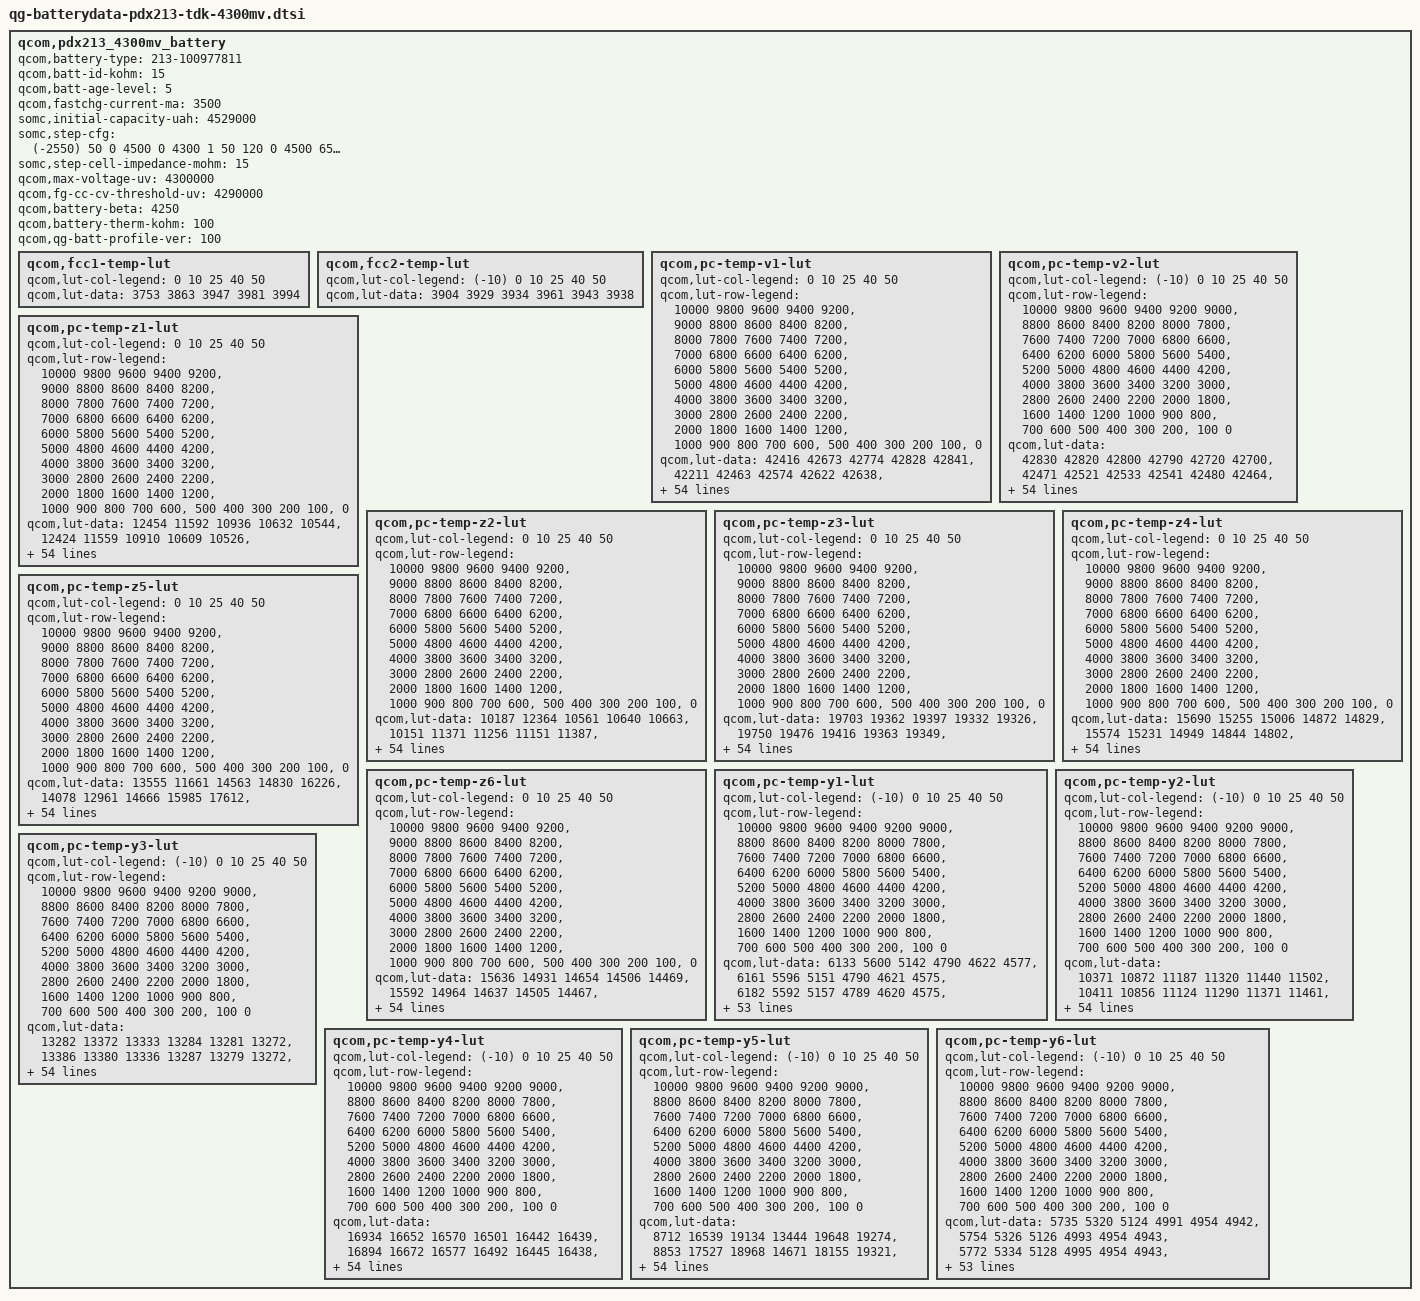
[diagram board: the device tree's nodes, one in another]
qcom,pdx213_4300mv_battery {
	/* Added or Modified by SOMC */
	qcom,battery-type = "213-100977811";
	qcom,batt-id-kohm = <15>;
	qcom,batt-age-level = <5>;
	qcom,fastchg-current-ma = <3500>;
	somc,initial-capacity-uah = <4529000>;
	somc,step-cfg = <
		(-2550) 50    0 4500    0 4300 1
		   50  120    0 4500  650 4300 2
		  120  150    0 4100 1750 4300 3
		  120  150 4100 4200 1300 4300 3
		  120  150 4200 4500  850 4300 3
		  150  200    0 4100 2150 4300 3
		  150  200 4100 4200 1500 4300 3
		  150  200 4200 4500  850 4300 3
		  200  450    0 4150 3050 4300 3
		  200  450 4150 4200 2150 4300 3
		  200  450 4200 4500 1300 4300 3
		  450  550    0 4500 1300 4200 4
		  550 2550    0 4500    0 4200 5
	>;
	somc,step-cell-impedance-mohm = <15>;

	/* Prepared by Qualcomm */
    /* 4764153_SoMC_Licht_4005mAh_averaged_MasterSlave_Aug31st2020 */
    qcom,max-voltage-uv = <4300000>;
    qcom,fg-cc-cv-threshold-uv = <4290000>;
    /* qcom,fastchg-current-ma = <1500>; */
    /* qcom,batt-id-kohm = <0>; */
    qcom,battery-beta = <4250>;
    qcom,battery-therm-kohm = <100>;
    /* qcom,battery-type = "4764153_SoMC_Licht_4005mAh_averaged_MasterSlave_Aug31st2020"; */
    qcom,qg-batt-profile-ver = <100>;

	qcom,fcc1-temp-lut {
		qcom,lut-col-legend = <0 10 25 40 50>;
		qcom,lut-data = <3753 3863 3947 3981 3994>;
	};

	qcom,fcc2-temp-lut {
		qcom,lut-col-legend = <(-10) 0 10 25 40 50>;
		qcom,lut-data = <3904 3929 3934 3961 3943 3938>;
	};

	qcom,pc-temp-v1-lut {
		qcom,lut-col-legend = <0 10 25 40 50>;
		qcom,lut-row-legend = <10000 9800 9600 9400 9200>,
			<9000 8800 8600 8400 8200>,
			<8000 7800 7600 7400 7200>,
			<7000 6800 6600 6400 6200>,
			<6000 5800 5600 5400 5200>,
			<5000 4800 4600 4400 4200>,
			<4000 3800 3600 3400 3200>,
			<3000 2800 2600 2400 2200>,
			<2000 1800 1600 1400 1200>,
			<1000 900 800 700 600>,
			<500 400 300 200 100>,
			<0>;
		qcom,lut-data = <42416 42673 42774 42828 42841>,
			<42211 42463 42574 42622 42638>,
			<42012 42243 42369 42415 42433>,
			<41815 42025 42156 42208 42227>,
			<41623 41819 41940 41999 42018>,
			<41435 41621 41731 41792 41811>,
			<41251 41429 41526 41586 41607>,
			<41072 41239 41328 41384 41407>,
			<40902 41053 41137 41188 41210>,
			<40741 40874 40951 40995 41015>,
			<40579 40700 40770 40808 40827>,
			<40405 40531 40592 40626 40645>,
			<40231 40365 40423 40451 40469>,
			<40079 40205 40263 40285 40301>,
			<39950 40055 40110 40127 40139>,
			<39828 39920 39962 39975 39983>,
			<39702 39785 39827 39835 39841>,
			<39577 39630 39671 39690 39698>,
			<39444 39458 39431 39496 39516>,
			<39290 39277 39160 39257 39289>,
			<39127 39060 38994 39067 39092>,
			<38978 38856 38896 38937 38950>,
			<38831 38756 38812 38827 38830>,
			<38709 38704 38727 38723 38723>,
			<38633 38657 38646 38628 38629>,
			<38578 38602 38568 38540 38541>,
			<38534 38546 38490 38458 38457>,
			<38496 38489 38418 38383 38377>,
			<38463 38431 38355 38314 38304>,
			<38430 38375 38298 38251 38236>,
			<38396 38326 38248 38194 38174>,
			<38363 38281 38202 38143 38118>,
			<38329 38240 38160 38096 38066>,
			<38296 38205 38120 38048 38012>,
			<38259 38171 38081 38002 37958>,
			<38220 38130 38039 37952 37901>,
			<38176 38086 37994 37897 37837>,
			<38115 38030 37942 37835 37766>,
			<38022 37945 37867 37759 37685>,
			<37908 37833 37763 37665 37593>,
			<37789 37712 37648 37559 37488>,
			<37654 37576 37518 37433 37361>,
			<37509 37433 37378 37297 37225>,
			<37363 37280 37226 37154 37088>,
			<37276 37175 37120 37055 36993>,
			<37199 37118 37067 37004 36944>,
			<37172 37096 37048 36991 36929>,
			<37145 37076 37036 36976 36916>,
			<37111 37054 37013 36954 36895>,
			<37036 36987 36941 36865 36780>,
			<36787 36713 36644 36548 36451>,
			<36343 36276 36211 36115 36018>,
			<35784 35714 35656 35559 35461>,
			<35024 34949 34910 34816 34713>,
			<33747 33698 33765 33675 33563>,
			<30000 30000 30000 30000 30000>;
	};

	qcom,pc-temp-v2-lut {
		qcom,lut-col-legend = <(-10) 0 10 25 40 50>;
		qcom,lut-row-legend = <10000 9800 9600 9400 9200 9000>,
			<8800 8600 8400 8200 8000 7800>,
			<7600 7400 7200 7000 6800 6600>,
			<6400 6200 6000 5800 5600 5400>,
			<5200 5000 4800 4600 4400 4200>,
			<4000 3800 3600 3400 3200 3000>,
			<2800 2600 2400 2200 2000 1800>,
			<1600 1400 1200 1000 900 800>,
			<700 600 500 400 300 200>,
			<100 0>;
		qcom,lut-data = <42830 42820 42800 42790 42720 42700>,
			<42471 42521 42533 42541 42480 42464>,
			<42157 42247 42280 42304 42249 42237>,
			<41894 41999 42046 42081 42030 42020>,
			<41679 41779 41828 41870 41820 41811>,
			<41479 41565 41618 41664 41616 41607>,
			<41285 41337 41410 41459 41416 41406>,
			<41099 41112 41208 41259 41220 41209>,
			<40908 40921 41015 41063 41028 41017>,
			<40714 40770 40831 40872 40839 40828>,
			<40512 40617 40652 40687 40656 40646>,
			<40289 40424 40470 40506 40479 40470>,
			<40049 40205 40290 40332 40307 40301>,
			<39826 40015 40122 40166 40143 40137>,
			<39629 39865 39973 40011 39989 39982>,
			<39437 39712 39817 39855 39836 39827>,
			<39219 39514 39615 39695 39681 39672>,
			<38979 39280 39374 39531 39524 39517>,
			<38771 39067 39161 39343 39347 39344>,
			<38600 38884 38979 39107 39119 39123>,
			<38456 38720 38818 38889 38902 38912>,
			<38354 38577 38684 38746 38760 38768>,
			<38277 38451 38567 38632 38650 38656>,
			<38213 38333 38461 38529 38552 38557>,
			<38155 38208 38361 38433 38458 38465>,
			<38104 38098 38270 38345 38372 38381>,
			<38054 38030 38185 38263 38293 38301>,
			<38007 37984 38105 38188 38221 38226>,
			<37959 37945 38029 38118 38153 38156>,
			<37912 37908 37955 38053 38092 38092>,
			<37865 37874 37887 37993 38034 38032>,
			<37816 37843 37838 37939 37973 37970>,
			<37765 37816 37803 37890 37913 37912>,
			<37711 37784 37770 37837 37847 37844>,
			<37653 37737 37738 37779 37768 37749>,
			<37592 37674 37705 37717 37682 37639>,
			<37524 37608 37664 37649 37599 37544>,
			<37445 37536 37609 37576 37520 37465>,
			<37359 37456 37540 37497 37438 37385>,
			<37272 37361 37454 37416 37353 37299>,
			<37181 37252 37346 37326 37264 37209>,
			<37091 37132 37223 37213 37156 37100>,
			<37010 36991 37071 37075 37017 36958>,
			<36929 36871 36937 36965 36921 36864>,
			<36843 36783 36834 36889 36867 36816>,
			<36748 36716 36765 36858 36842 36792>,
			<36696 36684 36738 36841 36827 36778>,
			<36639 36644 36706 36818 36808 36761>,
			<36562 36578 36644 36771 36771 36717>,
			<36448 36456 36515 36641 36617 36539>,
			<36248 36184 36207 36280 36261 36163>,
			<35900 35705 35707 35789 35775 35674>,
			<35355 35031 35068 35164 35154 35044>,
			<34477 34068 34184 34311 34307 34196>,
			<33236 32640 32846 33037 33207 33044>,
			<31414 29628 29526 29622 29720 29623>;
	};

	qcom,pc-temp-z1-lut {
		qcom,lut-col-legend = <0 10 25 40 50>;
		qcom,lut-row-legend = <10000 9800 9600 9400 9200>,
			<9000 8800 8600 8400 8200>,
			<8000 7800 7600 7400 7200>,
			<7000 6800 6600 6400 6200>,
			<6000 5800 5600 5400 5200>,
			<5000 4800 4600 4400 4200>,
			<4000 3800 3600 3400 3200>,
			<3000 2800 2600 2400 2200>,
			<2000 1800 1600 1400 1200>,
			<1000 900 800 700 600>,
			<500 400 300 200 100>,
			<0>;
		qcom,lut-data = <12454 11592 10936 10632 10544>,
			<12424 11559 10910 10609 10526>,
			<12403 11539 10892 10594 10513>,
			<12392 11523 10881 10586 10509>,
			<12383 11508 10873 10582 10506>,
			<12369 11493 10868 10580 10505>,
			<12333 11482 10864 10580 10504>,
			<12300 11474 10863 10580 10504>,
			<12295 11468 10862 10579 10504>,
			<12297 11465 10862 10579 10505>,
			<12298 11465 10863 10579 10505>,
			<12280 11464 10864 10580 10506>,
			<12250 11462 10865 10581 10507>,
			<12236 11459 10866 10582 10508>,
			<12243 11458 10867 10583 10509>,
			<12254 11465 10869 10584 10510>,
			<12255 11475 10873 10587 10512>,
			<12251 11481 10878 10589 10514>,
			<12248 11486 10882 10591 10515>,
			<12248 11490 10886 10594 10517>,
			<12247 11493 10890 10596 10518>,
			<12250 11496 10894 10599 10521>,
			<12261 11498 10898 10602 10525>,
			<12271 11501 10902 10606 10527>,
			<12274 11503 10907 10609 10529>,
			<12279 11506 10910 10612 10531>,
			<12281 11509 10914 10614 10533>,
			<12281 11512 10917 10617 10535>,
			<12283 11515 10922 10619 10536>,
			<12286 11517 10927 10622 10538>,
			<12297 11521 10930 10625 10540>,
			<12308 11527 10932 10627 10542>,
			<12315 11532 10934 10629 10544>,
			<12331 11535 10937 10631 10546>,
			<12340 11537 10942 10634 10548>,
			<12343 11541 10947 10637 10550>,
			<12346 11549 10950 10639 10552>,
			<12348 11557 10954 10642 10556>,
			<12357 11563 10960 10644 10557>,
			<12368 11570 10966 10647 10558>,
			<12379 11577 10971 10650 10560>,
			<12398 11586 10975 10653 10561>,
			<12399 11596 10981 10656 10563>,
			<12392 11613 10990 10659 10565>,
			<12407 11622 10998 10661 10567>,
			<12413 11618 10999 10662 10569>,
			<12407 11608 10996 10663 10568>,
			<12408 11613 10999 10663 10568>,
			<12425 11611 11003 10667 10571>,
			<12419 11629 11011 10672 10574>,
			<12419 11641 11022 10678 10579>,
			<12446 11670 11039 10687 10588>,
			<12464 11686 11056 10701 10599>,
			<12544 11727 11085 10722 10617>,
			<12544 11727 11085 10722 10617>,
			<12544 11727 11085 10722 10617>;
	};

	qcom,pc-temp-z2-lut {
		qcom,lut-col-legend = <0 10 25 40 50>;
		qcom,lut-row-legend = <10000 9800 9600 9400 9200>,
			<9000 8800 8600 8400 8200>,
			<8000 7800 7600 7400 7200>,
			<7000 6800 6600 6400 6200>,
			<6000 5800 5600 5400 5200>,
			<5000 4800 4600 4400 4200>,
			<4000 3800 3600 3400 3200>,
			<3000 2800 2600 2400 2200>,
			<2000 1800 1600 1400 1200>,
			<1000 900 800 700 600>,
			<500 400 300 200 100>,
			<0>;
		qcom,lut-data = <10187 12364 10561 10640 10663>,
			<10151 11371 11256 11151 11387>,
			<10120 10730 11477 11447 11810>,
			<10092 10332 11204 11501 11806>,
			<10067 10265 10826 11598 11654>,
			<10054 10247 10712 11739 11540>,
			<10047 10241 10759 11891 11470>,
			<10043 10250 10815 11994 11415>,
			<10043 10268 10900 11938 11415>,
			<10045 10283 11011 11744 11443>,
			<10049 10296 11053 11659 11454>,
			<10057 10308 11093 11710 11139>,
			<10072 10322 11137 11765 10750>,
			<10090 10336 11192 11552 10716>,
			<10115 10343 11242 10895 10742>,
			<10140 10345 11186 10600 10759>,
			<10154 10347 10831 10610 10759>,
			<10163 10362 10580 10625 10759>,
			<10175 10403 10584 11019 10771>,
			<10200 10424 10597 12396 10812>,
			<10232 10392 10592 13081 10860>,
			<10253 10347 10533 12181 10944>,
			<10267 10343 10488 11025 11027>,
			<10278 10366 10538 10820 10995>,
			<10284 10389 10638 10785 10794>,
			<10290 10402 10664 10761 10645>,
			<10292 10411 10625 10705 10608>,
			<10293 10416 10583 10653 10596>,
			<10293 10417 10569 10649 10595>,
			<10294 10418 10559 10655 10591>,
			<10300 10424 10558 10664 10596>,
			<10307 10438 10577 10684 10635>,
			<10311 10451 10607 10716 10704>,
			<10314 10460 10637 10761 10787>,
			<10317 10468 10674 10829 10903>,
			<10321 10477 10693 10892 10972>,
			<10326 10487 10699 10945 10981>,
			<10331 10498 10705 10988 10985>,
			<10336 10512 10725 11005 11001>,
			<10340 10526 10767 11013 11040>,
			<10336 10527 10788 11016 11063>,
			<10324 10509 10788 11022 11043>,
			<10327 10502 10788 11032 11013>,
			<10349 10520 10796 11050 10981>,
			<10152 10633 10833 10995 11008>,
			<9984 10650 10814 10949 11004>,
			<9880 10697 10805 10913 10997>,
			<9903 10735 10777 10900 11039>,
			<9954 10821 10787 10938 11136>,
			<9882 10869 10826 10996 11022>,
			<9878 10791 10972 10769 10698>,
			<9742 10745 10937 10715 10610>,
			<9535 10693 10921 10636 10561>,
			<9442 10506 10839 10523 10485>,
			<9442 10506 10839 10523 10485>,
			<9442 10506 10839 10523 10485>;
	};

	qcom,pc-temp-z3-lut {
		qcom,lut-col-legend = <0 10 25 40 50>;
		qcom,lut-row-legend = <10000 9800 9600 9400 9200>,
			<9000 8800 8600 8400 8200>,
			<8000 7800 7600 7400 7200>,
			<7000 6800 6600 6400 6200>,
			<6000 5800 5600 5400 5200>,
			<5000 4800 4600 4400 4200>,
			<4000 3800 3600 3400 3200>,
			<3000 2800 2600 2400 2200>,
			<2000 1800 1600 1400 1200>,
			<1000 900 800 700 600>,
			<500 400 300 200 100>,
			<0>;
		qcom,lut-data = <19703 19362 19397 19332 19326>,
			<19750 19476 19416 19363 19349>,
			<19783 19557 19435 19386 19365>,
			<19803 19608 19459 19402 19371>,
			<19818 19615 19478 19414 19375>,
			<19821 19615 19482 19417 19375>,
			<19818 19614 19476 19413 19369>,
			<19814 19607 19474 19407 19360>,
			<19812 19596 19473 19402 19357>,
			<19810 19593 19471 19396 19356>,
			<19809 19594 19468 19393 19354>,
			<19802 19595 19464 19391 19344>,
			<19791 19590 19459 19389 19331>,
			<19781 19579 19456 19377 19328>,
			<19770 19573 19452 19350 19327>,
			<19762 19571 19445 19339 19325>,
			<19762 19570 19428 19340 19323>,
			<19764 19573 19418 19342 19321>,
			<19765 19581 19428 19344 19321>,
			<19768 19586 19447 19348 19322>,
			<19771 19588 19449 19353 19325>,
			<19772 19589 19427 19354 19349>,
			<19772 19586 19409 19356 19380>,
			<19773 19573 19412 19366 19383>,
			<19772 19563 19422 19390 19373>,
			<19767 19565 19433 19400 19366>,
			<19761 19570 19457 19398 19362>,
			<19755 19575 19474 19394 19360>,
			<19748 19581 19472 19390 19356>,
			<19743 19586 19463 19383 19351>,
			<19738 19585 19455 19377 19345>,
			<19734 19580 19448 19370 19340>,
			<19730 19574 19441 19365 19335>,
			<19726 19568 19435 19359 19330>,
			<19722 19562 19430 19353 19325>,
			<19718 19557 19427 19350 19322>,
			<19714 19555 19425 19350 19323>,
			<19709 19551 19423 19350 19324>,
			<19703 19546 19419 19350 19324>,
			<19696 19539 19413 19347 19324>,
			<19690 19535 19409 19345 19324>,
			<19683 19532 19406 19347 19327>,
			<19672 19527 19404 19348 19331>,
			<19646 19517 19402 19348 19333>,
			<19412 19482 19393 19340 19326>,
			<19323 19453 19382 19336 19316>,
			<19291 19439 19382 19328 19317>,
			<19282 19412 19372 19327 19313>,
			<19286 19344 19373 19323 19302>,
			<19264 19354 19358 19324 19321>,
			<19264 19378 19347 19346 19341>,
			<19266 19334 19346 19353 19342>,
			<19271 19329 19346 19359 19345>,
			<19282 19331 19344 19355 19348>,
			<19282 19331 19344 19355 19348>,
			<19282 19331 19344 19355 19348>;
	};

	qcom,pc-temp-z4-lut {
		qcom,lut-col-legend = <0 10 25 40 50>;
		qcom,lut-row-legend = <10000 9800 9600 9400 9200>,
			<9000 8800 8600 8400 8200>,
			<8000 7800 7600 7400 7200>,
			<7000 6800 6600 6400 6200>,
			<6000 5800 5600 5400 5200>,
			<5000 4800 4600 4400 4200>,
			<4000 3800 3600 3400 3200>,
			<3000 2800 2600 2400 2200>,
			<2000 1800 1600 1400 1200>,
			<1000 900 800 700 600>,
			<500 400 300 200 100>,
			<0>;
		qcom,lut-data = <15690 15255 15006 14872 14829>,
			<15574 15231 14949 14844 14802>,
			<15470 15158 14899 14813 14776>,
			<15373 15068 14850 14772 14749>,
			<15286 15009 14811 14723 14719>,
			<15216 14962 14787 14696 14702>,
			<15161 14922 14757 14687 14698>,
			<15113 14886 14740 14680 14695>,
			<15066 14856 14725 14674 14689>,
			<15019 14840 14707 14668 14679>,
			<14994 14828 14700 14662 14672>,
			<14992 14823 14694 14652 14675>,
			<14991 14824 14690 14645 14679>,
			<14985 14826 14684 14652 14675>,
			<14952 14826 14680 14676 14667>,
			<14913 14809 14681 14686 14662>,
			<14893 14790 14696 14683 14661>,
			<14878 14796 14720 14679 14661>,
			<14872 14827 14799 14710 14682>,
			<14895 14869 14911 14805 14770>,
			<14944 14956 14942 14847 14821>,
			<14991 15049 14945 14846 14795>,
			<15045 15062 14947 14842 14756>,
			<15084 15032 14933 14825 14740>,
			<15084 14996 14897 14781 14733>,
			<15073 14965 14862 14749 14726>,
			<15057 14934 14820 14734 14716>,
			<15040 14909 14788 14723 14704>,
			<15019 14889 14777 14714 14696>,
			<15000 14875 14771 14707 14688>,
			<14982 14867 14767 14702 14683>,
			<14965 14861 14764 14698 14678>,
			<14952 14856 14762 14696 14674>,
			<14941 14852 14762 14697 14675>,
			<14930 14848 14764 14704 14683>,
			<14919 14845 14766 14713 14693>,
			<14909 14842 14770 14724 14705>,
			<14901 14840 14774 14733 14716>,
			<14895 14836 14776 14735 14717>,
			<14889 14833 14779 14736 14715>,
			<14877 14826 14780 14736 14713>,
			<14858 14812 14773 14732 14711>,
			<14834 14796 14764 14727 14708>,
			<14812 14779 14757 14727 14706>,
			<14918 14727 14727 14716 14698>,
			<14990 14714 14692 14686 14679>,
			<15014 14713 14676 14673 14659>,
			<15016 14732 14665 14652 14642>,
			<15005 14802 14656 14645 14640>,
			<15022 14789 14679 14660 14645>,
			<15029 14780 14717 14661 14642>,
			<15041 14833 14720 14655 14643>,
			<15047 14842 14720 14651 14642>,
			<15055 14850 14724 14656 14640>,
			<15055 14850 14724 14656 14640>,
			<15055 14850 14724 14656 14640>;
	};

	qcom,pc-temp-z5-lut {
		qcom,lut-col-legend = <0 10 25 40 50>;
		qcom,lut-row-legend = <10000 9800 9600 9400 9200>,
			<9000 8800 8600 8400 8200>,
			<8000 7800 7600 7400 7200>,
			<7000 6800 6600 6400 6200>,
			<6000 5800 5600 5400 5200>,
			<5000 4800 4600 4400 4200>,
			<4000 3800 3600 3400 3200>,
			<3000 2800 2600 2400 2200>,
			<2000 1800 1600 1400 1200>,
			<1000 900 800 700 600>,
			<500 400 300 200 100>,
			<0>;
		qcom,lut-data = <13555 11661 14563 14830 16226>,
			<14078 12961 14666 15985 17612>,
			<14613 14771 14966 17518 19060>,
			<15179 16459 16494 19697 20707>,
			<15751 17338 18352 22527 22811>,
			<16261 17873 19531 24204 23687>,
			<16680 18439 21379 25103 23067>,
			<17110 19162 22363 25585 22249>,
			<17724 19980 22736 25661 22566>,
			<18593 21020 23304 26074 24167>,
			<19297 22589 23822 26863 24958>,
			<19745 23616 24483 29229 23007>,
			<20192 23129 25171 31411 20575>,
			<20612 21961 25958 29264 20516>,
			<21045 21631 26630 22235 21585>,
			<21678 23661 26480 19145 22458>,
			<23228 26683 24990 20562 22916>,
			<26629 29399 23936 22105 23215>,
			<30051 32319 26682 22040 22505>,
			<33205 33577 31496 21291 19397>,
			<36002 32930 31741 20337 17635>,
			<36714 31600 24617 18094 18245>,
			<36407 29682 18648 15967 19088>,
			<35852 25817 18025 16222 19136>,
			<34888 23239 17846 17942 18740>,
			<33053 23270 18303 19614 18502>,
			<31372 23494 21451 20899 19193>,
			<30108 23955 25038 22143 20468>,
			<29080 26082 27034 23407 21480>,
			<28783 28611 28588 24676 22474>,
			<28772 30166 29770 25922 23506>,
			<28808 31453 30800 27455 24899>,
			<28948 31928 31472 28674 26137>,
			<29302 31883 31681 28682 26171>,
			<29660 31793 31811 28027 25284>,
			<29956 31711 31790 27254 24204>,
			<30236 31616 30952 26524 23064>,
			<30436 31469 29563 25651 21877>,
			<30633 30876 27990 24277 20967>,
			<30768 29922 25997 22107 20141>,
			<30654 29407 24649 20986 19772>,
			<30122 29185 23942 21060 20354>,
			<29403 28966 23520 21116 20924>,
			<27923 28476 23082 20494 20486>,
			<16293 28408 24480 19838 19112>,
			<12164 23015 24797 21111 18590>,
			<11711 20444 26539 20593 20897>,
			<11513 17813 24151 24113 24631>,
			<11555 13273 25874 25851 22156>,
			<11363 13719 19938 20697 24163>,
			<11377 15153 15791 21206 27880>,
			<11327 12812 15336 23011 26919>,
			<11274 12570 14930 24084 27264>,
			<11659 12782 14439 21601 27511>,
			<11659 12782 14439 21601 27511>,
			<11659 12782 14439 21601 27511>;
	};

	qcom,pc-temp-z6-lut {
		qcom,lut-col-legend = <0 10 25 40 50>;
		qcom,lut-row-legend = <10000 9800 9600 9400 9200>,
			<9000 8800 8600 8400 8200>,
			<8000 7800 7600 7400 7200>,
			<7000 6800 6600 6400 6200>,
			<6000 5800 5600 5400 5200>,
			<5000 4800 4600 4400 4200>,
			<4000 3800 3600 3400 3200>,
			<3000 2800 2600 2400 2200>,
			<2000 1800 1600 1400 1200>,
			<1000 900 800 700 600>,
			<500 400 300 200 100>,
			<0>;
		qcom,lut-data = <15636 14931 14654 14506 14469>,
			<15592 14964 14637 14505 14467>,
			<15549 14956 14623 14503 14463>,
			<15506 14943 14613 14495 14456>,
			<15463 14925 14604 14480 14445>,
			<15425 14898 14592 14469 14436>,
			<15390 14872 14578 14462 14430>,
			<15358 14849 14566 14457 14425>,
			<15330 14829 14558 14451 14420>,
			<15304 14820 14552 14445 14415>,
			<15284 14816 14546 14440 14410>,
			<15271 14812 14542 14435 14405>,
			<15260 14809 14538 14431 14401>,
			<15246 14805 14534 14426 14396>,
			<15223 14800 14530 14422 14392>,
			<15205 14792 14529 14420 14390>,
			<15201 14786 14530 14419 14388>,
			<15200 14790 14530 14419 14387>,
			<15199 14810 14567 14434 14397>,
			<15212 14835 14629 14480 14437>,
			<15239 14875 14643 14502 14460>,
			<15263 14915 14637 14502 14461>,
			<15289 14920 14629 14501 14461>,
			<15308 14903 14621 14498 14460>,
			<15308 14885 14614 14493 14453>,
			<15302 14874 14608 14486 14444>,
			<15295 14865 14603 14479 14438>,
			<15287 14859 14598 14472 14432>,
			<15278 14855 14593 14466 14426>,
			<15270 14852 14587 14460 14421>,
			<15263 14849 14581 14454 14415>,
			<15257 14845 14576 14448 14409>,
			<15252 14842 14572 14444 14404>,
			<15248 14839 14570 14443 14404>,
			<15245 14836 14569 14444 14405>,
			<15244 14836 14569 14445 14407>,
			<15243 14836 14570 14449 14412>,
			<15243 14837 14572 14454 14417>,
			<15246 14837 14572 14455 14418>,
			<15250 14836 14572 14454 14418>,
			<15250 14836 14571 14454 14417>,
			<15247 14833 14569 14453 14418>,
			<15243 14829 14565 14452 14419>,
			<15234 14823 14563 14453 14419>,
			<15180 14793 14548 14445 14413>,
			<15171 14777 14528 14429 14400>,
			<15170 14771 14521 14419 14391>,
			<15169 14767 14512 14410 14382>,
			<15173 14766 14510 14405 14375>,
			<15181 14773 14515 14413 14387>,
			<15198 14791 14528 14427 14399>,
			<15221 14801 14533 14430 14402>,
			<15246 14814 14538 14434 14405>,
			<15291 14840 14546 14438 14410>,
			<15291 14840 14546 14438 14410>,
			<15291 14840 14546 14438 14410>;
	};

	qcom,pc-temp-y1-lut {
		qcom,lut-col-legend = <(-10) 0 10 25 40 50>;
		qcom,lut-row-legend = <10000 9800 9600 9400 9200 9000>,
			<8800 8600 8400 8200 8000 7800>,
			<7600 7400 7200 7000 6800 6600>,
			<6400 6200 6000 5800 5600 5400>,
			<5200 5000 4800 4600 4400 4200>,
			<4000 3800 3600 3400 3200 3000>,
			<2800 2600 2400 2200 2000 1800>,
			<1600 1400 1200 1000 900 800>,
			<700 600 500 400 300 200>,
			<100 0>;
		qcom,lut-data = <6133 5600 5142 4790 4622 4577>,
			<6161 5596 5151 4790 4621 4575>,
			<6182 5592 5157 4789 4620 4575>,
			<6197 5587 5160 4789 4619 4574>,
			<6205 5583 5161 4788 4619 4574>,
			<6207 5581 5161 4787 4618 4574>,
			<6201 5581 5158 4786 4618 4575>,
			<6188 5582 5153 4786 4619 4575>,
			<6185 5584 5151 4785 4619 4575>,
			<6193 5599 5152 4784 4619 4575>,
			<6202 5611 5153 4784 4619 4575>,
			<6201 5607 5153 4784 4619 4576>,
			<6195 5596 5151 4785 4619 4577>,
			<6193 5593 5151 4785 4620 4577>,
			<6208 5598 5153 4787 4620 4578>,
			<6225 5604 5156 4788 4621 4578>,
			<6221 5603 5157 4789 4621 4578>,
			<6201 5599 5158 4790 4622 4579>,
			<6190 5598 5159 4791 4623 4580>,
			<6195 5614 5162 4794 4625 4581>,
			<6203 5634 5164 4798 4626 4581>,
			<6203 5632 5165 4800 4627 4582>,
			<6195 5617 5166 4802 4628 4583>,
			<6189 5609 5166 4804 4629 4583>,
			<6197 5614 5167 4807 4631 4584>,
			<6212 5622 5168 4811 4632 4585>,
			<6215 5622 5169 4814 4633 4586>,
			<6208 5619 5172 4818 4635 4587>,
			<6200 5617 5174 4821 4637 4588>,
			<6193 5614 5178 4824 4639 4590>,
			<6186 5608 5182 4827 4641 4592>,
			<6185 5610 5184 4830 4644 4593>,
			<6194 5629 5188 4834 4646 4594>,
			<6205 5643 5190 4837 4648 4596>,
			<6206 5633 5190 4839 4648 4596>,
			<6205 5613 5189 4841 4649 4597>,
			<6204 5607 5191 4843 4650 4598>,
			<6197 5608 5194 4845 4651 4600>,
			<6187 5610 5198 4847 4652 4601>,
			<6186 5611 5202 4849 4654 4601>,
			<6187 5612 5208 4852 4655 4601>,
			<6190 5612 5209 4855 4656 4602>,
			<6211 5607 5207 4859 4657 4603>,
			<6234 5605 5208 4867 4659 4604>,
			<6243 5616 5217 4875 4661 4604>,
			<6264 5614 5223 4876 4662 4606>,
			<6282 5621 5228 4873 4664 4607>,
			<6295 5647 5228 4876 4664 4608>,
			<6323 5636 5224 4878 4664 4607>,
			<6363 5659 5225 4884 4664 4607>,
			<6401 5677 5231 4882 4666 4610>,
			<6438 5714 5246 4895 4671 4614>,
			<6440 5751 5253 4912 4677 4618>,
			<6438 5783 5312 4929 4686 4626>,
			<6438 5783 5312 4929 4686 4626>,
			<6438 5783 5312 4929 4686 4626>;
	};

	qcom,pc-temp-y2-lut {
		qcom,lut-col-legend = <(-10) 0 10 25 40 50>;
		qcom,lut-row-legend = <10000 9800 9600 9400 9200 9000>,
			<8800 8600 8400 8200 8000 7800>,
			<7600 7400 7200 7000 6800 6600>,
			<6400 6200 6000 5800 5600 5400>,
			<5200 5000 4800 4600 4400 4200>,
			<4000 3800 3600 3400 3200 3000>,
			<2800 2600 2400 2200 2000 1800>,
			<1600 1400 1200 1000 900 800>,
			<700 600 500 400 300 200>,
			<100 0>;
		qcom,lut-data = <10371 10872 11187 11320 11440 11502>,
			<10411 10856 11124 11290 11371 11461>,
			<10478 10831 11060 11257 11299 11407>,
			<10554 10805 11000 11224 11233 11349>,
			<10619 10783 10949 11192 11186 11297>,
			<10654 10771 10910 11165 11165 11261>,
			<10659 10767 10881 11138 11176 11238>,
			<10662 10765 10859 11112 11198 11218>,
			<10667 10769 10855 11098 11208 11208>,
			<10681 10806 10866 11085 11212 11200>,
			<10702 10852 10884 11078 11214 11196>,
			<10735 10879 10914 11084 11214 11218>,
			<10782 10900 10964 11100 11214 11270>,
			<10814 10929 11022 11122 11217 11299>,
			<10831 10977 11107 11157 11246 11309>,
			<10842 11020 11172 11203 11296 11320>,
			<10688 11033 11178 11278 11402 11410>,
			<10101 11040 11177 11370 11572 11613>,
			<9746 11048 11179 11395 11631 11693>,
			<9718 11061 11190 11372 11562 11627>,
			<9703 11071 11206 11352 11488 11554>,
			<9694 11067 11221 11360 11484 11558>,
			<9688 11046 11236 11385 11491 11598>,
			<9684 11035 11251 11410 11502 11633>,
			<9681 11069 11266 11437 11523 11653>,
			<9678 11116 11279 11464 11552 11674>,
			<9676 11119 11282 11487 11596 11716>,
			<9674 11085 11278 11508 11678 11792>,
			<9672 11042 11274 11529 11728 11841>,
			<9670 10998 11274 11556 11765 11854>,
			<9669 10949 11273 11578 11809 11864>,
			<9668 10903 11268 11584 11824 11907>,
			<9667 10867 11251 11585 11852 12052>,
			<9665 10811 11229 11584 11863 12146>,
			<9665 10488 11204 11576 11809 12070>,
			<9664 9934 11176 11562 11727 11928>,
			<9664 9736 11144 11543 11700 11869>,
			<9663 9709 11108 11514 11692 11852>,
			<9663 9694 11067 11486 11690 11835>,
			<9662 9685 11017 11466 11697 11804>,
			<9662 9678 10958 11444 11708 11764>,
			<9661 9673 10884 11414 11703 11739>,
			<9660 9670 10791 11369 11644 11726>,
			<9659 9668 10609 11297 11581 11697>,
			<9657 9665 10128 11206 11485 11561>,
			<9655 9663 9812 11171 11450 11326>,
			<9654 9662 9795 11234 11392 11323>,
			<9653 9661 9791 11233 11415 11420>,
			<9652 9659 9728 11234 11449 11430>,
			<9651 9657 9697 11210 11417 11363>,
			<9650 9654 9682 11144 11343 11278>,
			<9649 9651 9669 11051 11271 11183>,
			<9648 9649 9660 10961 11194 11121>,
			<9648 9650 9660 10881 11093 11005>,
			<9648 9650 9660 10881 11093 11005>,
			<9648 9650 9660 10881 11093 11005>;
	};

	qcom,pc-temp-y3-lut {
		qcom,lut-col-legend = <(-10) 0 10 25 40 50>;
		qcom,lut-row-legend = <10000 9800 9600 9400 9200 9000>,
			<8800 8600 8400 8200 8000 7800>,
			<7600 7400 7200 7000 6800 6600>,
			<6400 6200 6000 5800 5600 5400>,
			<5200 5000 4800 4600 4400 4200>,
			<4000 3800 3600 3400 3200 3000>,
			<2800 2600 2400 2200 2000 1800>,
			<1600 1400 1200 1000 900 800>,
			<700 600 500 400 300 200>,
			<100 0>;
		qcom,lut-data = <13282 13372 13333 13284 13281 13272>,
			<13386 13380 13336 13287 13279 13272>,
			<13460 13389 13338 13291 13277 13273>,
			<13510 13397 13340 13294 13277 13274>,
			<13537 13403 13343 13297 13278 13275>,
			<13547 13406 13345 13299 13279 13275>,
			<13526 13405 13347 13300 13282 13276>,
			<13484 13403 13349 13301 13285 13277>,
			<13471 13400 13351 13301 13287 13278>,
			<13483 13397 13354 13302 13288 13278>,
			<13495 13394 13355 13303 13288 13279>,
			<13492 13395 13354 13304 13289 13281>,
			<13478 13398 13353 13306 13289 13284>,
			<13466 13399 13352 13307 13289 13285>,
			<13457 13398 13352 13309 13291 13284>,
			<13449 13395 13352 13310 13293 13284>,
			<13440 13390 13349 13310 13293 13285>,
			<13430 13381 13342 13309 13292 13286>,
			<13421 13373 13335 13307 13292 13287>,
			<13413 13368 13331 13300 13285 13282>,
			<13407 13364 13327 13294 13279 13275>,
			<13407 13360 13326 13294 13278 13274>,
			<13412 13357 13325 13293 13279 13273>,
			<13419 13353 13325 13293 13279 13273>,
			<13431 13340 13324 13293 13278 13273>,
			<13449 13325 13323 13293 13276 13274>,
			<13470 13323 13322 13293 13276 13274>,
			<13495 13326 13320 13293 13277 13274>,
			<13523 13330 13319 13294 13277 13274>,
			<13553 13334 13318 13294 13278 13273>,
			<13586 13339 13317 13294 13279 13273>,
			<13623 13344 13317 13294 13279 13273>,
			<13666 13352 13318 13294 13279 13274>,
			<13713 13360 13320 13294 13279 13275>,
			<13763 13367 13323 13294 13278 13274>,
			<13815 13374 13326 13294 13277 13272>,
			<13869 13384 13329 13294 13277 13272>,
			<13925 13401 13331 13293 13276 13272>,
			<13983 13423 13333 13292 13276 13273>,
			<14043 13448 13334 13293 13276 13273>,
			<14106 13478 13335 13294 13277 13274>,
			<14176 13515 13337 13295 13277 13274>,
			<14249 13561 13339 13296 13276 13272>,
			<14349 13624 13342 13298 13276 13271>,
			<14559 13720 13347 13301 13280 13274>,
			<14946 13859 13368 13306 13282 13280>,
			<15222 13907 13372 13304 13285 13283>,
			<15349 13947 13376 13308 13290 13285>,
			<15806 14100 13406 13313 13293 13285>,
			<16876 14347 13445 13315 13289 13282>,
			<18855 14921 13495 13309 13285 13281>,
			<23276 16304 13606 13314 13287 13282>,
			<35288 20098 13925 13324 13290 13284>,
			<65535 33676 14922 13333 13293 13287>,
			<65535 33676 14922 13333 13293 13287>,
			<65535 33676 14922 13333 13293 13287>;
	};

	qcom,pc-temp-y4-lut {
		qcom,lut-col-legend = <(-10) 0 10 25 40 50>;
		qcom,lut-row-legend = <10000 9800 9600 9400 9200 9000>,
			<8800 8600 8400 8200 8000 7800>,
			<7600 7400 7200 7000 6800 6600>,
			<6400 6200 6000 5800 5600 5400>,
			<5200 5000 4800 4600 4400 4200>,
			<4000 3800 3600 3400 3200 3000>,
			<2800 2600 2400 2200 2000 1800>,
			<1600 1400 1200 1000 900 800>,
			<700 600 500 400 300 200>,
			<100 0>;
		qcom,lut-data = <16934 16652 16570 16501 16442 16439>,
			<16894 16672 16577 16492 16445 16438>,
			<16875 16696 16583 16487 16447 16437>,
			<16874 16718 16589 16484 16449 16437>,
			<16886 16738 16594 16484 16450 16438>,
			<16908 16751 16599 16484 16451 16439>,
			<16988 16758 16602 16486 16450 16440>,
			<17121 16763 16606 16491 16449 16442>,
			<17160 16779 16613 16495 16449 16444>,
			<17122 16851 16631 16501 16452 16448>,
			<17068 16911 16653 16507 16457 16452>,
			<17017 16890 16673 16513 16463 16454>,
			<16961 16835 16694 16521 16471 16456>,
			<16919 16816 16713 16530 16479 16459>,
			<16892 16826 16734 16543 16487 16468>,
			<16868 16836 16748 16558 16496 16481>,
			<16842 16817 16728 16574 16512 16495>,
			<16815 16755 16664 16592 16534 16510>,
			<16791 16701 16615 16593 16540 16514>,
			<16769 16667 16582 16541 16502 16484>,
			<16751 16638 16560 16490 16461 16450>,
			<16749 16614 16551 16484 16456 16447>,
			<16754 16594 16546 16482 16455 16447>,
			<16758 16580 16542 16482 16455 16448>,
			<16758 16571 16540 16485 16461 16451>,
			<16757 16565 16538 16490 16470 16457>,
			<16756 16564 16535 16496 16478 16464>,
			<16754 16567 16532 16502 16488 16472>,
			<16752 16571 16528 16509 16497 16481>,
			<16754 16577 16518 16518 16508 16492>,
			<16757 16586 16507 16526 16518 16502>,
			<16760 16596 16506 16533 16519 16506>,
			<16764 16606 16517 16540 16519 16507>,
			<16767 16620 16531 16543 16518 16508>,
			<16768 16649 16549 16534 16508 16496>,
			<16767 16689 16570 16520 16490 16474>,
			<16766 16706 16589 16509 16480 16466>,
			<16764 16712 16608 16497 16471 16463>,
			<16761 16715 16622 16493 16467 16461>,
			<16761 16714 16628 16497 16468 16460>,
			<16764 16710 16633 16502 16469 16460>,
			<16769 16704 16633 16505 16468 16458>,
			<16777 16680 16622 16505 16459 16448>,
			<16795 16668 16617 16505 16454 16444>,
			<16867 16677 16631 16504 16453 16447>,
			<17009 16713 16675 16526 16471 16454>,
			<17094 16727 16679 16523 16474 16461>,
			<17059 16734 16682 16533 16481 16487>,
			<17152 16770 16719 16550 16519 16525>,
			<17411 16810 16742 16562 16505 16497>,
			<17867 16939 16737 16521 16458 16448>,
			<19112 17345 16739 16532 16454 16447>,
			<24843 19484 16833 16562 16465 16456>,
			<65535 38319 17598 16615 16500 16491>,
			<65535 38319 17598 16615 16500 16491>,
			<65535 38319 17598 16615 16500 16491>;
	};

	qcom,pc-temp-y5-lut {
		qcom,lut-col-legend = <(-10) 0 10 25 40 50>;
		qcom,lut-row-legend = <10000 9800 9600 9400 9200 9000>,
			<8800 8600 8400 8200 8000 7800>,
			<7600 7400 7200 7000 6800 6600>,
			<6400 6200 6000 5800 5600 5400>,
			<5200 5000 4800 4600 4400 4200>,
			<4000 3800 3600 3400 3200 3000>,
			<2800 2600 2400 2200 2000 1800>,
			<1600 1400 1200 1000 900 800>,
			<700 600 500 400 300 200>,
			<100 0>;
		qcom,lut-data = <8712 16539 19134 13444 19648 19274>,
			<8853 17527 18968 14671 18155 19321>,
			<13985 18102 18754 15706 17240 19268>,
			<17783 18358 18510 16506 16761 19134>,
			<20187 18385 18255 17027 16578 18936>,
			<21133 18277 18007 17225 16548 18692>,
			<19941 17291 17782 16977 17439 18394>,
			<17458 15576 17533 16442 19075 18025>,
			<16931 15144 17127 15999 19457 17563>,
			<20305 15781 16237 15571 18893 16827>,
			<23552 16672 15581 15238 18108 16328>,
			<23232 17452 15809 15057 17200 16747>,
			<21796 18308 16598 14956 16195 17706>,
			<21192 19382 17703 14939 15836 17932>,
			<21806 21156 20004 14959 15763 16620>,
			<22523 22596 22109 15121 15733 15350>,
			<21684 22843 22740 16085 16026 15724>,
			<17975 22924 23102 17920 16939 17165>,
			<14983 23022 23185 19058 17877 18565>,
			<13573 23196 22688 19683 18996 20032>,
			<12610 23417 22130 20094 19944 21110>,
			<12303 23699 22172 20338 20237 20743>,
			<12163 24093 22549 20536 20225 19145>,
			<12105 24241 22846 20568 19928 18146>,
			<12147 20321 22968 20225 18473 17932>,
			<12245 14842 23079 19877 16931 17787>,
			<12352 13914 23301 19937 16773 17494>,
			<12531 14146 23689 20196 16883 16915>,
			<12723 14466 23889 20425 17048 16567>,
			<12862 14846 23307 20568 17485 16431>,
			<12982 15358 22237 20736 18077 16316>,
			<13098 16131 21512 21117 18474 16577>,
			<13206 17681 20923 21879 18907 17933>,
			<13318 18752 20595 22685 19246 18863>,
			<13475 17691 20544 23672 19515 18521>,
			<13677 15487 20527 24455 19741 17909>,
			<13763 14802 20440 24026 19748 17820>,
			<13678 14895 20136 22090 19487 18328>,
			<13518 14999 19776 20638 19162 18901>,
			<13339 15072 19363 19938 18770 19283>,
			<13094 15163 18840 19441 18352 19600>,
			<12960 15161 18624 19258 18373 19762>,
			<13068 14623 18652 19159 19312 19868>,
			<13198 14257 18477 19312 19903 19588>,
			<12875 14255 16642 19697 19752 17416>,
			<12337 14188 14517 17582 16455 18161>,
			<12107 14146 14315 17394 16614 19813>,
			<12129 14093 14248 17524 20099 21697>,
			<11783 14067 14181 18164 21079 19955>,
			<11254 14218 14478 19798 19158 19480>,
			<10550 12976 14496 20135 20759 22732>,
			<9684 11219 14242 20994 23026 23887>,
			<9087 9733 13791 22610 25028 24261>,
			<8815 9005 11238 23504 26428 26374>,
			<8815 9005 11238 23504 26428 26374>,
			<8815 9005 11238 23504 26428 26374>;
	};

	qcom,pc-temp-y6-lut {
		qcom,lut-col-legend = <(-10) 0 10 25 40 50>;
		qcom,lut-row-legend = <10000 9800 9600 9400 9200 9000>,
			<8800 8600 8400 8200 8000 7800>,
			<7600 7400 7200 7000 6800 6600>,
			<6400 6200 6000 5800 5600 5400>,
			<5200 5000 4800 4600 4400 4200>,
			<4000 3800 3600 3400 3200 3000>,
			<2800 2600 2400 2200 2000 1800>,
			<1600 1400 1200 1000 900 800>,
			<700 600 500 400 300 200>,
			<100 0>;
		qcom,lut-data = <5735 5320 5124 4991 4954 4942>,
			<5754 5326 5126 4993 4954 4943>,
			<5772 5334 5128 4995 4954 4943>,
			<5790 5343 5130 4997 4955 4944>,
			<5806 5350 5132 4998 4956 4945>,
			<5818 5353 5134 5000 4957 4946>,
			<5827 5352 5136 5002 4958 4947>,
			<5835 5351 5137 5003 4960 4948>,
			<5837 5352 5140 5005 4962 4950>,
			<5838 5371 5146 5007 4964 4951>,
			<5838 5387 5153 5009 4965 4953>,
			<5831 5382 5157 5012 4967 4955>,
			<5812 5371 5162 5015 4969 4957>,
			<5797 5366 5166 5019 4972 4959>,
			<5789 5369 5172 5024 4976 4962>,
			<5781 5371 5176 5029 4980 4965>,
			<5767 5364 5168 5033 4985 4969>,
			<5745 5342 5145 5037 4990 4975>,
			<5733 5325 5127 5036 4991 4976>,
			<5731 5315 5115 5017 4976 4963>,
			<5729 5308 5107 4998 4959 4949>,
			<5732 5304 5105 4996 4957 4947>,
			<5748 5301 5104 4996 4957 4946>,
			<5768 5298 5104 4996 4957 4946>,
			<5787 5293 5104 4997 4958 4947>,
			<5808 5288 5104 4999 4960 4950>,
			<5831 5289 5104 5001 4963 4952>,
			<5856 5301 5104 5004 4966 4954>,
			<5883 5316 5105 5006 4969 4957>,
			<5914 5332 5104 5009 4973 4960>,
			<5949 5350 5102 5012 4976 4962>,
			<5986 5372 5103 5015 4977 4964>,
			<6024 5399 5110 5018 4977 4965>,
			<6065 5427 5119 5019 4977 4966>,
			<6107 5453 5130 5017 4974 4962>,
			<6151 5480 5145 5014 4968 4954>,
			<6196 5509 5159 5011 4965 4952>,
			<6243 5541 5175 5008 4963 4952>,
			<6292 5576 5191 5006 4961 4951>,
			<6344 5613 5209 5009 4962 4952>,
			<6401 5654 5227 5012 4962 4952>,
			<6465 5697 5247 5015 4962 4952>,
			<6531 5743 5268 5017 4959 4948>,
			<6625 5802 5295 5020 4959 4946>,
			<6845 5894 5333 5025 4961 4949>,
			<7245 6031 5393 5036 4968 4956>,
			<7513 6082 5401 5032 4971 4960>,
			<7619 6126 5410 5039 4976 4969>,
			<8028 6271 5465 5048 4989 4980>,
			<8955 6501 5528 5054 4982 4970>,
			<10611 7051 5601 5039 4967 4955>,
			<14187 8280 5734 5050 4967 4956>,
			<24060 11694 6068 5071 4973 4960>,
			<64437 26077 7149 5101 4987 4974>,
			<64437 26077 7149 5101 4987 4974>,
			<64437 26077 7149 5101 4987 4974>;
	};

};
